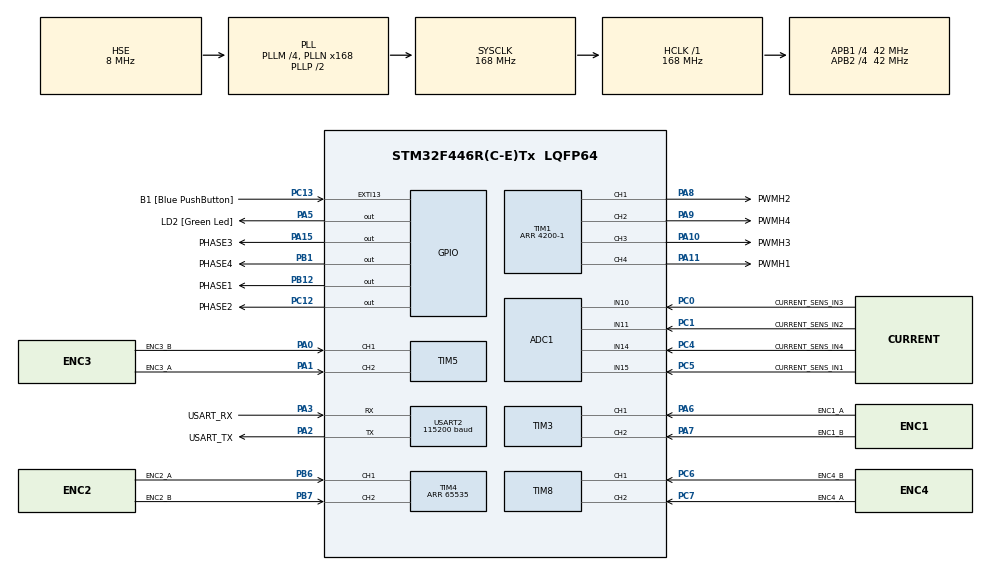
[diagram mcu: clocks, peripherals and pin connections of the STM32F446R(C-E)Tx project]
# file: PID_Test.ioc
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ADC1.Channel-0\#ChannelRegularConversion=ADC_CHANNEL_15
ADC1.Channel-4\#ChannelRegularConversion=ADC_CHANNEL_11
ADC1.Channel-5\#ChannelRegularConversion=ADC_CHANNEL_10
ADC1.Channel-6\#ChannelRegularConversion=ADC_CHANNEL_14
ADC1.ContinuousConvMode=ENABLE
ADC1.DMAContinuousRequests=ENABLE
ADC1.EOCSelection=ADC_EOC_SEQ_CONV
ADC1.NbrOfConversion=4
ADC1.NbrOfConversionFlag=1
ADC1.Rank-0\#ChannelRegularConversion=1
ADC1.Rank-4\#ChannelRegularConversion=2
ADC1.Rank-5\#ChannelRegularConversion=3
ADC1.Rank-6\#ChannelRegularConversion=4
ADC1.SamplingTime-0\#ChannelRegularConversion=ADC_SAMPLETIME_144CYCLES
ADC1.SamplingTime-4\#ChannelRegularConversion=ADC_SAMPLETIME_144CYCLES
ADC1.SamplingTime-5\#ChannelRegularConversion=ADC_SAMPLETIME_144CYCLES
ADC1.SamplingTime-6\#ChannelRegularConversion=ADC_SAMPLETIME_144CYCLES
ADC1.ScanConvMode=ENABLE
ADC1.master=1
Dma.ADC1.2.Direction=DMA_PERIPH_TO_MEMORY
Dma.ADC1.2.FIFOMode=DMA_FIFOMODE_DISABLE
Dma.ADC1.2.Instance=DMA2_Stream0
Dma.ADC1.2.MemDataAlignment=DMA_MDATAALIGN_HALFWORD
Dma.ADC1.2.MemInc=DMA_MINC_ENABLE
Dma.ADC1.2.Mode=DMA_CIRCULAR
Dma.ADC1.2.PeriphDataAlignment=DMA_PDATAALIGN_HALFWORD
Dma.ADC1.2.PeriphInc=DMA_PINC_DISABLE
Dma.ADC1.2.Priority=DMA_PRIORITY_LOW
Dma.Request0=USART2_RX
Dma.Request1=USART2_TX
Dma.Request2=ADC1
Dma.USART2_RX.0.Direction=DMA_PERIPH_TO_MEMORY
Dma.USART2_RX.0.FIFOMode=DMA_FIFOMODE_DISABLE
Dma.USART2_RX.0.Instance=DMA1_Stream5
Dma.USART2_RX.0.MemDataAlignment=DMA_MDATAALIGN_BYTE
Dma.USART2_RX.0.MemInc=DMA_MINC_ENABLE
Dma.USART2_RX.0.Mode=DMA_CIRCULAR
Dma.USART2_RX.0.PeriphDataAlignment=DMA_PDATAALIGN_BYTE
Dma.USART2_RX.0.PeriphInc=DMA_PINC_DISABLE
Dma.USART2_RX.0.Priority=DMA_PRIORITY_LOW
Dma.USART2_TX.1.Direction=DMA_MEMORY_TO_PERIPH
Dma.USART2_TX.1.FIFOMode=DMA_FIFOMODE_DISABLE
Dma.USART2_TX.1.Instance=DMA1_Stream6
Dma.USART2_TX.1.MemDataAlignment=DMA_MDATAALIGN_BYTE
Dma.USART2_TX.1.MemInc=DMA_MINC_ENABLE
Dma.USART2_TX.1.Mode=DMA_NORMAL
Dma.USART2_TX.1.PeriphDataAlignment=DMA_PDATAALIGN_BYTE
Dma.USART2_TX.1.PeriphInc=DMA_PINC_DISABLE
Dma.USART2_TX.1.Priority=DMA_PRIORITY_LOW
IWDG.Prescaler=IWDG_PRESCALER_8
IWDG.Reload=4000
Mcu.Family=STM32F4
Mcu.Name=STM32F446R(C-E)Tx
Mcu.Package=LQFP64
NVIC.DMA1_Stream5_IRQn=true\:1\:0\:true\:false\:true\:false\:true
NVIC.DMA1_Stream6_IRQn=true\:0\:0\:false\:false\:true\:false\:true
NVIC.DMA2_Stream0_IRQn=true\:0\:0\:false\:false\:true\:false\:true
NVIC.PriorityGroup=NVIC_PRIORITYGROUP_4
NVIC.TIM1_BRK_TIM9_IRQn=true\:1\:0\:true\:false\:true\:true\:true
NVIC.TIM1_UP_TIM10_IRQn=true\:1\:0\:true\:false\:true\:true\:true
NVIC.TIM6_DAC_IRQn=true\:0\:0\:false\:false\:true\:false\:true
NVIC.TIM7_IRQn=true\:2\:0\:true\:false\:true\:true\:true
NVIC.TimeBase=TIM6_DAC_IRQn
NVIC.TimeBaseIP=TIM6
NVIC.USART2_IRQn=true\:0\:0\:false\:false\:true\:true\:true
PA0-WKUP.GPIO_Label=ENC3_B
PA0-WKUP.Signal=S_TIM5_CH1
PA1.GPIO_Label=ENC3_A
PA1.Signal=S_TIM5_CH2
PA10.GPIO_Label=PWMH3
PA10.Signal=S_TIM1_CH3
PA11.GPIO_Label=PWMH1
PA11.Signal=S_TIM1_CH4
PA13.GPIO_Label=TMS
PA13.Mode=Serial_Wire
PA13.Signal=SYS_JTMS-SWDIO
PA14.GPIO_Label=TCK
PA14.Mode=Serial_Wire
PA14.Signal=SYS_JTCK-SWCLK
PA15.GPIO_Label=PHASE3
PA15.Signal=GPIO_Output
PA2.GPIO_Label=USART_TX
PA2.Mode=Asynchronous
PA2.Signal=USART2_TX
PA3.GPIO_Label=USART_RX
PA3.Mode=Asynchronous
PA3.Signal=USART2_RX
PA5.GPIO_Label=LD2 [Green Led]
PA5.Signal=GPIO_Output
PA6.GPIO_Label=ENC1_A
PA6.Signal=S_TIM3_CH1
PA7.GPIO_Label=ENC1_B
PA7.Signal=S_TIM3_CH2
PA8.GPIO_Label=PWMH2
PA8.Signal=S_TIM1_CH1
PA9.GPIO_Label=PWMH4
PA9.Signal=S_TIM1_CH2
PB1.GPIO_Label=PHASE4
PB1.Signal=GPIO_Output
PB12.GPIO_Label=PHASE1
PB12.Signal=GPIO_Output
PB3.GPIO_Label=SWO
PB3.Signal=SYS_JTDO-SWO
PB6.GPIO_Label=ENC2_A
PB6.Signal=S_TIM4_CH1
PB7.GPIO_Label=ENC2_B
PB7.Signal=S_TIM4_CH2
PC0.GPIO_Label=CURRENT_SENS_IN3
PC0.Signal=ADCx_IN10
PC1.GPIO_Label=CURRENT_SENS_IN2
PC1.Signal=ADCx_IN11
PC12.GPIO_Label=PHASE2
PC12.Signal=GPIO_Output
PC13.GPIO_Label=B1 [Blue PushButton]
PC13.GPIO_ModeDefaultEXTI=GPIO_MODE_IT_FALLING
PC13.Signal=GPXTI13
PC14-OSC32_IN.Mode=LSE-External-Oscillator
PC14-OSC32_IN.Signal=RCC_OSC32_IN
PC15-OSC32_OUT.Mode=LSE-External-Oscillator
PC15-OSC32_OUT.Signal=RCC_OSC32_OUT
PC4.GPIO_Label=CURRENT_SENS_IN4
PC4.Signal=ADCx_IN14
PC5.GPIO_Label=CURRENT_SENS_IN1
PC5.Signal=ADCx_IN15
PC6.GPIO_Label=ENC4_B
PC6.Signal=S_TIM8_CH1
PC7.GPIO_Label=ENC4_A
PC7.Signal=S_TIM8_CH2
PH0-OSC_IN.Mode=HSE-External-Oscillator
PH0-OSC_IN.Signal=RCC_OSC_IN
PH1-OSC_OUT.Mode=HSE-External-Oscillator
PH1-OSC_OUT.Signal=RCC_OSC_OUT
ProjectManager.HeapSize=0x200
ProjectManager.StackSize=0x400
ProjectManager.TargetToolchain=STM32CubeIDE
RCC.48MHZClocksFreq_Value=84000000
RCC.AHBFreq_Value=168000000
RCC.APB1CLKDivider=RCC_HCLK_DIV4
RCC.APB1Freq_Value=42000000
RCC.APB1TimFreq_Value=84000000
RCC.APB2CLKDivider=RCC_HCLK_DIV4
RCC.APB2Freq_Value=42000000
RCC.APB2TimFreq_Value=84000000
RCC.CortexFreq_Value=168000000
RCC.FLatency-AdvancedSettings=FLASH_LATENCY_5
RCC.HCLKFreq_Value=168000000
RCC.HSE_VALUE=8000000
RCC.HSI_VALUE=16000000
RCC.PLLM=4
RCC.PLLN=168
RCC.PLLSourceVirtual=RCC_PLLSOURCE_HSE
RCC.SYSCLKFreq_VALUE=168000000
RCC.SYSCLKSource=RCC_SYSCLKSOURCE_PLLCLK
RCC.USBFreq_Value=168000000
RCC.VCOOutputFreq_Value=336000000
SH.ADCx_IN10.0=ADC1_IN10,IN10
SH.ADCx_IN11.0=ADC1_IN11,IN11
SH.ADCx_IN14.0=ADC1_IN14,IN14
SH.ADCx_IN15.0=ADC1_IN15,IN15
SH.S_TIM1_CH1.0=TIM1_CH1,PWM Generation1 CH1
SH.S_TIM1_CH2.0=TIM1_CH2,PWM Generation2 CH2
SH.S_TIM1_CH3.0=TIM1_CH3,PWM Generation3 CH3
SH.S_TIM1_CH4.0=TIM1_CH4,PWM Generation4 CH4
SH.S_TIM3_CH1.0=TIM3_CH1,Encoder_Interface
SH.S_TIM3_CH2.0=TIM3_CH2,Encoder_Interface
SH.S_TIM4_CH1.0=TIM4_CH1,Encoder_Interface
SH.S_TIM4_CH2.0=TIM4_CH2,Encoder_Interface
SH.S_TIM5_CH1.0=TIM5_CH1,Encoder_Interface
SH.S_TIM5_CH2.0=TIM5_CH2,Encoder_Interface
SH.S_TIM8_CH1.0=TIM8_CH1,Encoder_Interface
SH.S_TIM8_CH2.0=TIM8_CH2,Encoder_Interface
TIM1.Channel-PWM\ Generation1\ CH1=TIM_CHANNEL_1
TIM1.Channel-PWM\ Generation2\ CH2=TIM_CHANNEL_2
TIM1.Channel-PWM\ Generation3\ CH3=TIM_CHANNEL_3
TIM1.Channel-PWM\ Generation4\ CH4=TIM_CHANNEL_4
TIM1.OCFastMode_PWM-PWM\ Generation1\ CH1=TIM_OCFAST_ENABLE
TIM1.OCFastMode_PWM-PWM\ Generation3\ CH3=TIM_OCFAST_ENABLE
TIM1.Period=4200-1
TIM10.Period=168-1
TIM10.Prescaler=100-1
TIM3.CounterMode=TIM_COUNTERMODE_UP
TIM3.EncoderMode=TIM_ENCODERMODE_TI12
TIM3.IC1Polarity=TIM_ICPOLARITY_FALLING
TIM3.IC2Polarity=TIM_ICPOLARITY_RISING
TIM4.AutoReloadPreload=TIM_AUTORELOAD_PRELOAD_ENABLE
TIM4.CounterMode=TIM_COUNTERMODE_UP
TIM4.EncoderMode=TIM_ENCODERMODE_TI12
TIM4.IC1Polarity=TIM_ICPOLARITY_FALLING
TIM4.IC2Polarity=TIM_ICPOLARITY_RISING
TIM4.Period=65535
TIM5.EncoderMode=TIM_ENCODERMODE_TI12
TIM7.Period=840-1
TIM7.Prescaler=1000-1
TIM8.EncoderMode=TIM_ENCODERMODE_TI12
TIM9.Period=168-1
TIM9.Prescaler=1000-1
USART2.BaudRate=115200
USART2.VirtualMode=VM_ASYNC
VP_IWDG_VS_IWDG.Mode=IWDG_Activate
VP_SYS_VS_tim6.Mode=TIM6
VP_TIM10_VS_ClockSourceINT.Mode=Enable_Timer
VP_TIM1_VS_ClockSourceINT.Mode=Internal
VP_TIM2_VS_ClockSourceINT.Mode=Internal
VP_TIM7_VS_ClockSourceINT.Mode=Enable_Timer
VP_TIM9_VS_ClockSourceINT.Mode=Internal
board=NUCLEO-F446RE

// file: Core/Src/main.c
/* USER CODE BEGIN Header */
/**
  ******************************************************************************
  * @file           : main.c
  * @brief          : Main program body
  ******************************************************************************
  * @attention
  *
  * <h2><center>&copy; Copyright (c) 2021 STMicroelectronics.
  * All rights reserved.</center></h2>
  *
  * This software component is licensed by ST under Ultimate Liberty license
  * SLA0044, the "License"; You may not use this file except in compliance with
  * the License. You may obtain a copy of the License at:
  *                             www.st.com/SLA0044
  *
  ******************************************************************************
  */
/* USER CODE END Header */
#include "main.h"

/* USER CODE BEGIN Includes */
#include <stdio.h>
/* USER CODE END Includes */

ADC_HandleTypeDef hadc1;
DMA_HandleTypeDef hdma_adc1;

IWDG_HandleTypeDef hiwdg;

TIM_HandleTypeDef htim1;
TIM_HandleTypeDef htim2;
TIM_HandleTypeDef htim3;
TIM_HandleTypeDef htim4;
TIM_HandleTypeDef htim5;
TIM_HandleTypeDef htim7;
TIM_HandleTypeDef htim8;
TIM_HandleTypeDef htim9;
TIM_HandleTypeDef htim10;

UART_HandleTypeDef huart2;
DMA_HandleTypeDef hdma_usart2_rx;
DMA_HandleTypeDef hdma_usart2_tx;

/* USER CODE BEGIN PV */
//extern uint16_t dt_pid, dt_main;
/* USER CODE END PV */

void SystemClock_Config(void);
static void MX_GPIO_Init(void);
static void MX_DMA_Init(void);
static void MX_USART2_UART_Init(void);
static void MX_TIM4_Init(void);
static void MX_TIM1_Init(void);
static void MX_TIM2_Init(void);
static void MX_TIM5_Init(void);
static void MX_TIM8_Init(void);
static void MX_TIM3_Init(void);
static void MX_TIM7_Init(void);
static void MX_TIM9_Init(void);
static void MX_TIM10_Init(void);
static void MX_ADC1_Init(void);
static void MX_IWDG_Init(void);
/* USER CODE BEGIN PFP */
void SetParams(void);
void MainLoop(void);
void VelCtrlLoop(void);
void CurrentCtrlLoop(void);
/* USER CODE END PFP */

int main(void)
{

  /* MCU Configuration--------------------------------------------------------*/

  /* Reset of all peripherals, Initializes the Flash interface and the Systick. */
  HAL_Init();

  /* Configure the system clock */
  SystemClock_Config();

  /* Initialize all configured peripherals */
  MX_GPIO_Init();
  MX_DMA_Init();
  MX_USART2_UART_Init();
  MX_TIM4_Init();
  MX_TIM1_Init();
  MX_TIM2_Init();
  MX_TIM5_Init();
  MX_TIM8_Init();
  MX_TIM3_Init();
  MX_TIM7_Init();
  MX_TIM9_Init();
  MX_TIM10_Init();
  MX_ADC1_Init();
  MX_IWDG_Init();
  /* USER CODE BEGIN 2 */
  SetParams();

  //start pid and main loop
  HAL_TIM_Base_Start_IT(&htim7);
  HAL_TIM_Base_Start_IT(&htim9);
  HAL_TIM_Base_Start_IT(&htim10);
  /* USER CODE END 2 */

  /* Infinite loop */
  while (1)
  {

  }
}

void SystemClock_Config(void)
{
  RCC_OscInitTypeDef RCC_OscInitStruct = {0};
  RCC_ClkInitTypeDef RCC_ClkInitStruct = {0};

  /** Configure the main internal regulator output voltage
  */
  __HAL_RCC_PWR_CLK_ENABLE();
  __HAL_PWR_VOLTAGESCALING_CONFIG(PWR_REGULATOR_VOLTAGE_SCALE1);
  /** Initializes the RCC Oscillators according to the specified parameters
  * in the RCC_OscInitTypeDef structure.
  */
  RCC_OscInitStruct.OscillatorType = RCC_OSCILLATORTYPE_LSI|RCC_OSCILLATORTYPE_HSE;
  RCC_OscInitStruct.HSEState = RCC_HSE_ON;
  RCC_OscInitStruct.LSIState = RCC_LSI_ON;
  RCC_OscInitStruct.PLL.PLLState = RCC_PLL_ON;
  RCC_OscInitStruct.PLL.PLLSource = RCC_PLLSOURCE_HSE;
  RCC_OscInitStruct.PLL.PLLM = 4;
  RCC_OscInitStruct.PLL.PLLN = 168;
  RCC_OscInitStruct.PLL.PLLP = RCC_PLLP_DIV2;
  RCC_OscInitStruct.PLL.PLLQ = 2;
  RCC_OscInitStruct.PLL.PLLR = 2;
  if (HAL_RCC_OscConfig(&RCC_OscInitStruct) != HAL_OK)
  {
    Error_Handler();
  }
  /** Initializes the CPU, AHB and APB buses clocks
  */
  RCC_ClkInitStruct.ClockType = RCC_CLOCKTYPE_HCLK|RCC_CLOCKTYPE_SYSCLK
                              |RCC_CLOCKTYPE_PCLK1|RCC_CLOCKTYPE_PCLK2;
  RCC_ClkInitStruct.SYSCLKSource = RCC_SYSCLKSOURCE_PLLCLK;
  RCC_ClkInitStruct.AHBCLKDivider = RCC_SYSCLK_DIV1;
  RCC_ClkInitStruct.APB1CLKDivider = RCC_HCLK_DIV4;
  RCC_ClkInitStruct.APB2CLKDivider = RCC_HCLK_DIV4;

  if (HAL_RCC_ClockConfig(&RCC_ClkInitStruct, FLASH_LATENCY_5) != HAL_OK)
  {
    Error_Handler();
  }
}

static void MX_ADC1_Init(void)
{

  ADC_ChannelConfTypeDef sConfig = {0};

  /** Configure the global features of the ADC (Clock, Resolution, Data Alignment and number of conversion)
  */
  hadc1.Instance = ADC1;
  hadc1.Init.ClockPrescaler = ADC_CLOCK_SYNC_PCLK_DIV2;
  hadc1.Init.Resolution = ADC_RESOLUTION_12B;
  hadc1.Init.ScanConvMode = ENABLE;
  hadc1.Init.ContinuousConvMode = ENABLE;
  hadc1.Init.DiscontinuousConvMode = DISABLE;
  hadc1.Init.ExternalTrigConvEdge = ADC_EXTERNALTRIGCONVEDGE_NONE;
  hadc1.Init.ExternalTrigConv = ADC_SOFTWARE_START;
  hadc1.Init.DataAlign = ADC_DATAALIGN_RIGHT;
  hadc1.Init.NbrOfConversion = 4;
  hadc1.Init.DMAContinuousRequests = ENABLE;
  hadc1.Init.EOCSelection = ADC_EOC_SEQ_CONV;
  if (HAL_ADC_Init(&hadc1) != HAL_OK)
  {
    Error_Handler();
  }
  /** Configure for the selected ADC regular channel its corresponding rank in the sequencer and its sample time.
  */
  sConfig.Channel = ADC_CHANNEL_15;
  sConfig.Rank = 1;
  sConfig.SamplingTime = ADC_SAMPLETIME_144CYCLES;
  if (HAL_ADC_ConfigChannel(&hadc1, &sConfig) != HAL_OK)
  {
    Error_Handler();
  }
  /** Configure for the selected ADC regular channel its corresponding rank in the sequencer and its sample time.
  */
  sConfig.Channel = ADC_CHANNEL_11;
  sConfig.Rank = 2;
  if (HAL_ADC_ConfigChannel(&hadc1, &sConfig) != HAL_OK)
  {
    Error_Handler();
  }
  /** Configure for the selected ADC regular channel its corresponding rank in the sequencer and its sample time.
  */
  sConfig.Channel = ADC_CHANNEL_10;
  sConfig.Rank = 3;
  if (HAL_ADC_ConfigChannel(&hadc1, &sConfig) != HAL_OK)
  {
    Error_Handler();
  }
  /** Configure for the selected ADC regular channel its corresponding rank in the sequencer and its sample time.
  */
  sConfig.Channel = ADC_CHANNEL_14;
  sConfig.Rank = 4;
  if (HAL_ADC_ConfigChannel(&hadc1, &sConfig) != HAL_OK)
  {
    Error_Handler();
  }

}

static void MX_IWDG_Init(void)
{

  hiwdg.Instance = IWDG;
  hiwdg.Init.Prescaler = IWDG_PRESCALER_8;
  hiwdg.Init.Reload = 4000;
  if (HAL_IWDG_Init(&hiwdg) != HAL_OK)
  {
    Error_Handler();
  }

}

static void MX_TIM1_Init(void)
{

  TIM_ClockConfigTypeDef sClockSourceConfig = {0};
  TIM_MasterConfigTypeDef sMasterConfig = {0};
  TIM_OC_InitTypeDef sConfigOC = {0};
  TIM_BreakDeadTimeConfigTypeDef sBreakDeadTimeConfig = {0};

  htim1.Instance = TIM1;
  htim1.Init.Prescaler = 0;
  htim1.Init.CounterMode = TIM_COUNTERMODE_UP;
  htim1.Init.Period = 4200-1;
  htim1.Init.ClockDivision = TIM_CLOCKDIVISION_DIV1;
  htim1.Init.RepetitionCounter = 0;
  htim1.Init.AutoReloadPreload = TIM_AUTORELOAD_PRELOAD_DISABLE;
  if (HAL_TIM_Base_Init(&htim1) != HAL_OK)
  {
    Error_Handler();
  }
  sClockSourceConfig.ClockSource = TIM_CLOCKSOURCE_INTERNAL;
  if (HAL_TIM_ConfigClockSource(&htim1, &sClockSourceConfig) != HAL_OK)
  {
    Error_Handler();
  }
  if (HAL_TIM_PWM_Init(&htim1) != HAL_OK)
  {
    Error_Handler();
  }
  sMasterConfig.MasterOutputTrigger = TIM_TRGO_RESET;
  sMasterConfig.MasterSlaveMode = TIM_MASTERSLAVEMODE_DISABLE;
  if (HAL_TIMEx_MasterConfigSynchronization(&htim1, &sMasterConfig) != HAL_OK)
  {
    Error_Handler();
  }
  sConfigOC.OCMode = TIM_OCMODE_PWM1;
  sConfigOC.Pulse = 0;
  sConfigOC.OCPolarity = TIM_OCPOLARITY_HIGH;
  sConfigOC.OCNPolarity = TIM_OCNPOLARITY_HIGH;
  sConfigOC.OCFastMode = TIM_OCFAST_ENABLE;
  sConfigOC.OCIdleState = TIM_OCIDLESTATE_RESET;
  sConfigOC.OCNIdleState = TIM_OCNIDLESTATE_RESET;
  if (HAL_TIM_PWM_ConfigChannel(&htim1, &sConfigOC, TIM_CHANNEL_1) != HAL_OK)
  {
    Error_Handler();
  }
  sConfigOC.OCFastMode = TIM_OCFAST_DISABLE;
  if (HAL_TIM_PWM_ConfigChannel(&htim1, &sConfigOC, TIM_CHANNEL_2) != HAL_OK)
  {
    Error_Handler();
  }
  sConfigOC.OCFastMode = TIM_OCFAST_ENABLE;
  if (HAL_TIM_PWM_ConfigChannel(&htim1, &sConfigOC, TIM_CHANNEL_3) != HAL_OK)
  {
    Error_Handler();
  }
  sConfigOC.OCFastMode = TIM_OCFAST_DISABLE;
  if (HAL_TIM_PWM_ConfigChannel(&htim1, &sConfigOC, TIM_CHANNEL_4) != HAL_OK)
  {
    Error_Handler();
  }
  sBreakDeadTimeConfig.OffStateRunMode = TIM_OSSR_DISABLE;
  sBreakDeadTimeConfig.OffStateIDLEMode = TIM_OSSI_DISABLE;
  sBreakDeadTimeConfig.LockLevel = TIM_LOCKLEVEL_OFF;
  sBreakDeadTimeConfig.DeadTime = 0;
  sBreakDeadTimeConfig.BreakState = TIM_BREAK_DISABLE;
  sBreakDeadTimeConfig.BreakPolarity = TIM_BREAKPOLARITY_HIGH;
  sBreakDeadTimeConfig.AutomaticOutput = TIM_AUTOMATICOUTPUT_DISABLE;
  if (HAL_TIMEx_ConfigBreakDeadTime(&htim1, &sBreakDeadTimeConfig) != HAL_OK)
  {
    Error_Handler();
  }
  HAL_TIM_MspPostInit(&htim1);

}

static void MX_TIM2_Init(void)
{

  TIM_ClockConfigTypeDef sClockSourceConfig = {0};
  TIM_MasterConfigTypeDef sMasterConfig = {0};

  htim2.Instance = TIM2;
  htim2.Init.Prescaler = 0;
  htim2.Init.CounterMode = TIM_COUNTERMODE_UP;
  htim2.Init.Period = 4294967295;
  htim2.Init.ClockDivision = TIM_CLOCKDIVISION_DIV1;
  htim2.Init.AutoReloadPreload = TIM_AUTORELOAD_PRELOAD_DISABLE;
  if (HAL_TIM_Base_Init(&htim2) != HAL_OK)
  {
    Error_Handler();
  }
  sClockSourceConfig.ClockSource = TIM_CLOCKSOURCE_INTERNAL;
  if (HAL_TIM_ConfigClockSource(&htim2, &sClockSourceConfig) != HAL_OK)
  {
    Error_Handler();
  }
  sMasterConfig.MasterOutputTrigger = TIM_TRGO_RESET;
  sMasterConfig.MasterSlaveMode = TIM_MASTERSLAVEMODE_DISABLE;
  if (HAL_TIMEx_MasterConfigSynchronization(&htim2, &sMasterConfig) != HAL_OK)
  {
    Error_Handler();
  }

}

static void MX_TIM3_Init(void)
{

  TIM_Encoder_InitTypeDef sConfig = {0};
  TIM_MasterConfigTypeDef sMasterConfig = {0};

  htim3.Instance = TIM3;
  htim3.Init.Prescaler = 0;
  htim3.Init.CounterMode = TIM_COUNTERMODE_UP;
  htim3.Init.Period = 65535;
  htim3.Init.ClockDivision = TIM_CLOCKDIVISION_DIV1;
  htim3.Init.AutoReloadPreload = TIM_AUTORELOAD_PRELOAD_DISABLE;
  sConfig.EncoderMode = TIM_ENCODERMODE_TI12;
  sConfig.IC1Polarity = TIM_ICPOLARITY_FALLING;
  sConfig.IC1Selection = TIM_ICSELECTION_DIRECTTI;
  sConfig.IC1Prescaler = TIM_ICPSC_DIV1;
  sConfig.IC1Filter = 0;
  sConfig.IC2Polarity = TIM_ICPOLARITY_RISING;
  sConfig.IC2Selection = TIM_ICSELECTION_DIRECTTI;
  sConfig.IC2Prescaler = TIM_ICPSC_DIV1;
  sConfig.IC2Filter = 0;
  if (HAL_TIM_Encoder_Init(&htim3, &sConfig) != HAL_OK)
  {
    Error_Handler();
  }
  sMasterConfig.MasterOutputTrigger = TIM_TRGO_RESET;
  sMasterConfig.MasterSlaveMode = TIM_MASTERSLAVEMODE_DISABLE;
  if (HAL_TIMEx_MasterConfigSynchronization(&htim3, &sMasterConfig) != HAL_OK)
  {
    Error_Handler();
  }

}

static void MX_TIM4_Init(void)
{

  TIM_Encoder_InitTypeDef sConfig = {0};
  TIM_MasterConfigTypeDef sMasterConfig = {0};

  htim4.Instance = TIM4;
  htim4.Init.Prescaler = 0;
  htim4.Init.CounterMode = TIM_COUNTERMODE_UP;
  htim4.Init.Period = 65535;
  htim4.Init.ClockDivision = TIM_CLOCKDIVISION_DIV1;
  htim4.Init.AutoReloadPreload = TIM_AUTORELOAD_PRELOAD_ENABLE;
  sConfig.EncoderMode = TIM_ENCODERMODE_TI12;
  sConfig.IC1Polarity = TIM_ICPOLARITY_FALLING;
  sConfig.IC1Selection = TIM_ICSELECTION_DIRECTTI;
  sConfig.IC1Prescaler = TIM_ICPSC_DIV1;
  sConfig.IC1Filter = 0;
  sConfig.IC2Polarity = TIM_ICPOLARITY_RISING;
  sConfig.IC2Selection = TIM_ICSELECTION_DIRECTTI;
  sConfig.IC2Prescaler = TIM_ICPSC_DIV1;
  sConfig.IC2Filter = 0;
  if (HAL_TIM_Encoder_Init(&htim4, &sConfig) != HAL_OK)
  {
    Error_Handler();
  }
  sMasterConfig.MasterOutputTrigger = TIM_TRGO_RESET;
  sMasterConfig.MasterSlaveMode = TIM_MASTERSLAVEMODE_DISABLE;
  if (HAL_TIMEx_MasterConfigSynchronization(&htim4, &sMasterConfig) != HAL_OK)
  {
    Error_Handler();
  }

}

static void MX_TIM5_Init(void)
{

  TIM_Encoder_InitTypeDef sConfig = {0};
  TIM_MasterConfigTypeDef sMasterConfig = {0};

  htim5.Instance = TIM5;
  htim5.Init.Prescaler = 0;
  htim5.Init.CounterMode = TIM_COUNTERMODE_UP;
  htim5.Init.Period = 4294967295;
  htim5.Init.ClockDivision = TIM_CLOCKDIVISION_DIV1;
  htim5.Init.AutoReloadPreload = TIM_AUTORELOAD_PRELOAD_DISABLE;
  sConfig.EncoderMode = TIM_ENCODERMODE_TI12;
  sConfig.IC1Polarity = TIM_ICPOLARITY_RISING;
  sConfig.IC1Selection = TIM_ICSELECTION_DIRECTTI;
  sConfig.IC1Prescaler = TIM_ICPSC_DIV1;
  sConfig.IC1Filter = 0;
  sConfig.IC2Polarity = TIM_ICPOLARITY_RISING;
  sConfig.IC2Selection = TIM_ICSELECTION_DIRECTTI;
  sConfig.IC2Prescaler = TIM_ICPSC_DIV1;
  sConfig.IC2Filter = 0;
  if (HAL_TIM_Encoder_Init(&htim5, &sConfig) != HAL_OK)
  {
    Error_Handler();
  }
  sMasterConfig.MasterOutputTrigger = TIM_TRGO_RESET;
  sMasterConfig.MasterSlaveMode = TIM_MASTERSLAVEMODE_DISABLE;
  if (HAL_TIMEx_MasterConfigSynchronization(&htim5, &sMasterConfig) != HAL_OK)
  {
    Error_Handler();
  }

}

static void MX_TIM7_Init(void)
{

  TIM_MasterConfigTypeDef sMasterConfig = {0};

  htim7.Instance = TIM7;
  htim7.Init.Prescaler = 1000-1;
  htim7.Init.CounterMode = TIM_COUNTERMODE_UP;
  htim7.Init.Period = 840-1;
  htim7.Init.AutoReloadPreload = TIM_AUTORELOAD_PRELOAD_DISABLE;
  if (HAL_TIM_Base_Init(&htim7) != HAL_OK)
  {
    Error_Handler();
  }
  sMasterConfig.MasterOutputTrigger = TIM_TRGO_RESET;
  sMasterConfig.MasterSlaveMode = TIM_MASTERSLAVEMODE_DISABLE;
  if (HAL_TIMEx_MasterConfigSynchronization(&htim7, &sMasterConfig) != HAL_OK)
  {
    Error_Handler();
  }

}

static void MX_TIM8_Init(void)
{

  TIM_Encoder_InitTypeDef sConfig = {0};
  TIM_MasterConfigTypeDef sMasterConfig = {0};

  htim8.Instance = TIM8;
  htim8.Init.Prescaler = 0;
  htim8.Init.CounterMode = TIM_COUNTERMODE_UP;
  htim8.Init.Period = 65535;
  htim8.Init.ClockDivision = TIM_CLOCKDIVISION_DIV1;
  htim8.Init.RepetitionCounter = 0;
  htim8.Init.AutoReloadPreload = TIM_AUTORELOAD_PRELOAD_DISABLE;
  sConfig.EncoderMode = TIM_ENCODERMODE_TI12;
  sConfig.IC1Polarity = TIM_ICPOLARITY_RISING;
  sConfig.IC1Selection = TIM_ICSELECTION_DIRECTTI;
  sConfig.IC1Prescaler = TIM_ICPSC_DIV1;
  sConfig.IC1Filter = 0;
  sConfig.IC2Polarity = TIM_ICPOLARITY_RISING;
  sConfig.IC2Selection = TIM_ICSELECTION_DIRECTTI;
  sConfig.IC2Prescaler = TIM_ICPSC_DIV1;
  sConfig.IC2Filter = 0;
  if (HAL_TIM_Encoder_Init(&htim8, &sConfig) != HAL_OK)
  {
    Error_Handler();
  }
  sMasterConfig.MasterOutputTrigger = TIM_TRGO_RESET;
  sMasterConfig.MasterSlaveMode = TIM_MASTERSLAVEMODE_DISABLE;
  if (HAL_TIMEx_MasterConfigSynchronization(&htim8, &sMasterConfig) != HAL_OK)
  {
    Error_Handler();
  }

}

static void MX_TIM9_Init(void)
{

  TIM_ClockConfigTypeDef sClockSourceConfig = {0};

  htim9.Instance = TIM9;
  htim9.Init.Prescaler = 1000-1;
  htim9.Init.CounterMode = TIM_COUNTERMODE_UP;
  htim9.Init.Period = 168-1;
  htim9.Init.ClockDivision = TIM_CLOCKDIVISION_DIV1;
  htim9.Init.AutoReloadPreload = TIM_AUTORELOAD_PRELOAD_DISABLE;
  if (HAL_TIM_Base_Init(&htim9) != HAL_OK)
  {
    Error_Handler();
  }
  sClockSourceConfig.ClockSource = TIM_CLOCKSOURCE_INTERNAL;
  if (HAL_TIM_ConfigClockSource(&htim9, &sClockSourceConfig) != HAL_OK)
  {
    Error_Handler();
  }

}

static void MX_TIM10_Init(void)
{

  htim10.Instance = TIM10;
  htim10.Init.Prescaler = 100-1;
  htim10.Init.CounterMode = TIM_COUNTERMODE_UP;
  htim10.Init.Period = 168-1;
  htim10.Init.ClockDivision = TIM_CLOCKDIVISION_DIV1;
  htim10.Init.AutoReloadPreload = TIM_AUTORELOAD_PRELOAD_DISABLE;
  if (HAL_TIM_Base_Init(&htim10) != HAL_OK)
  {
    Error_Handler();
  }

}

static void MX_USART2_UART_Init(void)
{

  huart2.Instance = USART2;
  huart2.Init.BaudRate = 115200;
  huart2.Init.WordLength = UART_WORDLENGTH_8B;
  huart2.Init.StopBits = UART_STOPBITS_1;
  huart2.Init.Parity = UART_PARITY_NONE;
  huart2.Init.Mode = UART_MODE_TX_RX;
  huart2.Init.HwFlowCtl = UART_HWCONTROL_NONE;
  huart2.Init.OverSampling = UART_OVERSAMPLING_16;
  if (HAL_UART_Init(&huart2) != HAL_OK)
  {
    Error_Handler();
  }

}

static void MX_DMA_Init(void)
{

  /* DMA controller clock enable */
  __HAL_RCC_DMA1_CLK_ENABLE();
  __HAL_RCC_DMA2_CLK_ENABLE();

  /* DMA interrupt init */
  /* DMA1_Stream5_IRQn interrupt configuration */
  HAL_NVIC_SetPriority(DMA1_Stream5_IRQn, 1, 0);
  HAL_NVIC_EnableIRQ(DMA1_Stream5_IRQn);
  /* DMA1_Stream6_IRQn interrupt configuration */
  HAL_NVIC_SetPriority(DMA1_Stream6_IRQn, 0, 0);
  HAL_NVIC_EnableIRQ(DMA1_Stream6_IRQn);
  /* DMA2_Stream0_IRQn interrupt configuration */
  HAL_NVIC_SetPriority(DMA2_Stream0_IRQn, 0, 0);
  HAL_NVIC_EnableIRQ(DMA2_Stream0_IRQn);

}

static void MX_GPIO_Init(void)
{
  GPIO_InitTypeDef GPIO_InitStruct = {0};

  /* GPIO Ports Clock Enable */
  __HAL_RCC_GPIOC_CLK_ENABLE();
  __HAL_RCC_GPIOH_CLK_ENABLE();
  __HAL_RCC_GPIOA_CLK_ENABLE();
  __HAL_RCC_GPIOB_CLK_ENABLE();

  /*Configure GPIO pin Output Level */
  HAL_GPIO_WritePin(GPIOA, LD2_Pin|PHASE3_Pin, GPIO_PIN_RESET);

  /*Configure GPIO pin Output Level */
  HAL_GPIO_WritePin(GPIOB, PHASE4_Pin|PHASE1_Pin, GPIO_PIN_RESET);

  /*Configure GPIO pin Output Level */
  HAL_GPIO_WritePin(PHASE2_GPIO_Port, PHASE2_Pin, GPIO_PIN_RESET);

  /*Configure GPIO pin : B1_Pin */
  GPIO_InitStruct.Pin = B1_Pin;
  GPIO_InitStruct.Mode = GPIO_MODE_IT_FALLING;
  GPIO_InitStruct.Pull = GPIO_NOPULL;
  HAL_GPIO_Init(B1_GPIO_Port, &GPIO_InitStruct);

  /*Configure GPIO pins : LD2_Pin PHASE3_Pin */
  GPIO_InitStruct.Pin = LD2_Pin|PHASE3_Pin;
  GPIO_InitStruct.Mode = GPIO_MODE_OUTPUT_PP;
  GPIO_InitStruct.Pull = GPIO_NOPULL;
  GPIO_InitStruct.Speed = GPIO_SPEED_FREQ_LOW;
  HAL_GPIO_Init(GPIOA, &GPIO_InitStruct);

  /*Configure GPIO pins : PHASE4_Pin PHASE1_Pin */
  GPIO_InitStruct.Pin = PHASE4_Pin|PHASE1_Pin;
  GPIO_InitStruct.Mode = GPIO_MODE_OUTPUT_PP;
  GPIO_InitStruct.Pull = GPIO_NOPULL;
  GPIO_InitStruct.Speed = GPIO_SPEED_FREQ_LOW;
  HAL_GPIO_Init(GPIOB, &GPIO_InitStruct);

  /*Configure GPIO pin : PHASE2_Pin */
  GPIO_InitStruct.Pin = PHASE2_Pin;
  GPIO_InitStruct.Mode = GPIO_MODE_OUTPUT_PP;
  GPIO_InitStruct.Pull = GPIO_NOPULL;
  GPIO_InitStruct.Speed = GPIO_SPEED_FREQ_LOW;
  HAL_GPIO_Init(PHASE2_GPIO_Port, &GPIO_InitStruct);

}

 /**
  * @brief  Period elapsed callback in non blocking mode
  * @note   This function is called  when TIM6 interrupt took place, inside
  * HAL_TIM_IRQHandler(). It makes a direct call to HAL_IncTick() to increment
  * a global variable "uwTick" used as application time base.
  * @param  htim : TIM handle
  * @retval None
  */
void HAL_TIM_PeriodElapsedCallback(TIM_HandleTypeDef *htim)
{
  if (htim->Instance == TIM6) {
    HAL_IncTick();
  }
  /* USER CODE BEGIN Callback 1 */
  else if(htim == &htim7) MainLoop();
  else if(htim == &htim9) VelCtrlLoop();
  else if(htim == &htim10) CurrentCtrlLoop();
  /* USER CODE END Callback 1 */
}

void Error_Handler(void)
{
  __disable_irq();
  while (1)
  {
  }
}

/************************ (C) COPYRIGHT STMicroelectronics *****END OF FILE****/
